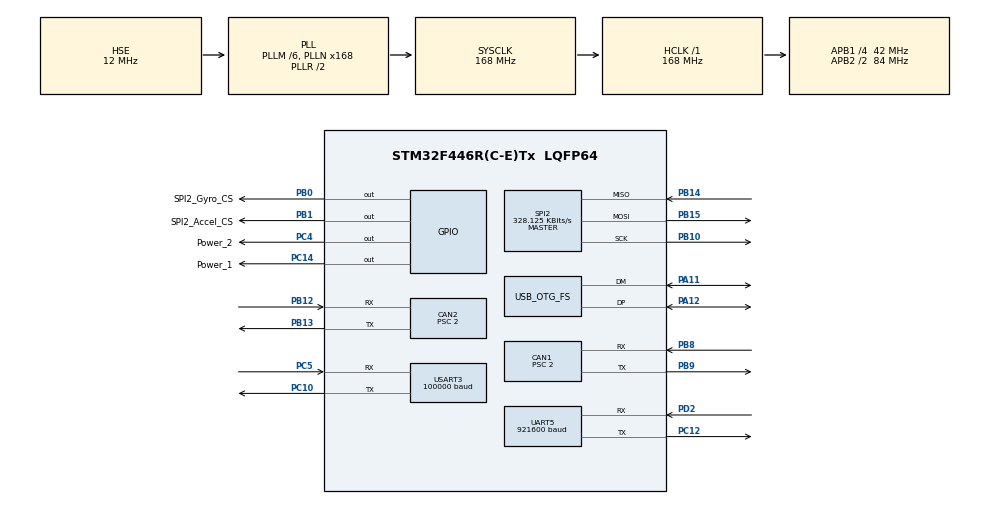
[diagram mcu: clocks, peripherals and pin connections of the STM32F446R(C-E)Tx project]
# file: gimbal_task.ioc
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CAN1.BS1=CAN_BS1_15TQ
CAN1.BS2=CAN_BS2_5TQ
CAN1.CalculateBaudRate=1000000
CAN1.CalculateTimeBit=1000
CAN1.CalculateTimeQuantum=47.61904761904762
CAN1.Prescaler=2
CAN2.BS1=CAN_BS1_15TQ
CAN2.BS2=CAN_BS2_5TQ
CAN2.CalculateBaudRate=1000000
CAN2.CalculateTimeBit=1000
CAN2.CalculateTimeQuantum=47.61904761904762
CAN2.Prescaler=2
Dma.Request0=SPI2_RX
Dma.Request1=SPI2_TX
Dma.Request2=USART3_RX
Dma.Request3=UART5_RX
Dma.SPI2_RX.0.Direction=DMA_PERIPH_TO_MEMORY
Dma.SPI2_RX.0.FIFOMode=DMA_FIFOMODE_DISABLE
Dma.SPI2_RX.0.Instance=DMA1_Stream3
Dma.SPI2_RX.0.MemDataAlignment=DMA_MDATAALIGN_BYTE
Dma.SPI2_RX.0.MemInc=DMA_MINC_ENABLE
Dma.SPI2_RX.0.Mode=DMA_NORMAL
Dma.SPI2_RX.0.PeriphDataAlignment=DMA_PDATAALIGN_BYTE
Dma.SPI2_RX.0.PeriphInc=DMA_PINC_DISABLE
Dma.SPI2_RX.0.Priority=DMA_PRIORITY_HIGH
Dma.SPI2_TX.1.Direction=DMA_MEMORY_TO_PERIPH
Dma.SPI2_TX.1.FIFOMode=DMA_FIFOMODE_DISABLE
Dma.SPI2_TX.1.Instance=DMA1_Stream4
Dma.SPI2_TX.1.MemDataAlignment=DMA_MDATAALIGN_BYTE
Dma.SPI2_TX.1.MemInc=DMA_MINC_ENABLE
Dma.SPI2_TX.1.Mode=DMA_NORMAL
Dma.SPI2_TX.1.PeriphDataAlignment=DMA_PDATAALIGN_BYTE
Dma.SPI2_TX.1.PeriphInc=DMA_PINC_DISABLE
Dma.SPI2_TX.1.Priority=DMA_PRIORITY_VERY_HIGH
Dma.UART5_RX.3.Direction=DMA_PERIPH_TO_MEMORY
Dma.UART5_RX.3.FIFOMode=DMA_FIFOMODE_DISABLE
Dma.UART5_RX.3.Instance=DMA1_Stream0
Dma.UART5_RX.3.MemDataAlignment=DMA_MDATAALIGN_BYTE
Dma.UART5_RX.3.MemInc=DMA_MINC_ENABLE
Dma.UART5_RX.3.Mode=DMA_NORMAL
Dma.UART5_RX.3.PeriphDataAlignment=DMA_PDATAALIGN_BYTE
Dma.UART5_RX.3.PeriphInc=DMA_PINC_DISABLE
Dma.UART5_RX.3.Priority=DMA_PRIORITY_LOW
Dma.USART3_RX.2.Direction=DMA_PERIPH_TO_MEMORY
Dma.USART3_RX.2.FIFOMode=DMA_FIFOMODE_DISABLE
Dma.USART3_RX.2.Instance=DMA1_Stream1
Dma.USART3_RX.2.MemDataAlignment=DMA_MDATAALIGN_BYTE
Dma.USART3_RX.2.MemInc=DMA_MINC_ENABLE
Dma.USART3_RX.2.Mode=DMA_NORMAL
Dma.USART3_RX.2.PeriphDataAlignment=DMA_PDATAALIGN_BYTE
Dma.USART3_RX.2.PeriphInc=DMA_PINC_DISABLE
Dma.USART3_RX.2.Priority=DMA_PRIORITY_LOW
FREERTOS.Tasks01=defaultTask,0,128,StartDefaultTask,Default,NULL,Dynamic,NULL,NULL;GIMABL,0,128,gimbal_task,As weak,NULL,Dynamic,NULL,NULL;INS,0,128,ins_task,As weak,NULL,Dynamic,NULL,NULL;SHOOT,0,128,shoot_task,As weak,NULL,Dynamic,NULL,NULL;STATE,0,128,state_task,As weak,NULL,Dynamic,NULL,NULL;VISION,0,128,vision_task,As weak,NULL,Dynamic,NULL,NULL
Mcu.Family=STM32F4
Mcu.Name=STM32F446R(C-E)Tx
Mcu.Package=LQFP64
NVIC.CAN1_RX0_IRQn=true\:5\:0\:false\:false\:true\:true\:true\:true\:true
NVIC.CAN2_RX0_IRQn=true\:5\:0\:false\:false\:true\:true\:true\:true\:true
NVIC.DMA1_Stream0_IRQn=true\:5\:0\:false\:false\:true\:true\:false\:true\:true
NVIC.DMA1_Stream1_IRQn=true\:5\:0\:false\:false\:true\:true\:false\:true\:true
NVIC.DMA1_Stream3_IRQn=true\:5\:0\:false\:false\:true\:true\:false\:true\:true
NVIC.DMA1_Stream4_IRQn=true\:5\:0\:false\:false\:true\:true\:false\:true\:true
NVIC.OTG_FS_IRQn=true\:5\:0\:false\:false\:true\:true\:false\:true\:true
NVIC.PriorityGroup=NVIC_PRIORITYGROUP_4
NVIC.UART5_IRQn=true\:5\:0\:false\:false\:true\:true\:true\:true\:true
NVIC.USART3_IRQn=true\:5\:0\:false\:false\:true\:true\:true\:true\:true
PA11.Mode=Device_Only
PA11.Signal=USB_OTG_FS_DM
PA12.Mode=Device_Only
PA12.Signal=USB_OTG_FS_DP
PA13.Mode=Serial_Wire
PA13.Signal=SYS_JTMS-SWDIO
PA14.Mode=Serial_Wire
PA14.Signal=SYS_JTCK-SWCLK
PB0.GPIO_Label=SPI2_Gyro_CS
PB0.Signal=GPIO_Output
PB1.GPIO_Label=SPI2_Accel_CS
PB1.Signal=GPIO_Output
PB10.Mode=Full_Duplex_Master
PB10.Signal=SPI2_SCK
PB12.Mode=CAN_Activate
PB12.Signal=CAN2_RX
PB13.Mode=CAN_Activate
PB13.Signal=CAN2_TX
PB14.Mode=Full_Duplex_Master
PB14.Signal=SPI2_MISO
PB15.Mode=Full_Duplex_Master
PB15.Signal=SPI2_MOSI
PB8.Mode=CAN_Activate
PB8.Signal=CAN1_RX
PB9.Mode=CAN_Activate
PB9.Signal=CAN1_TX
PC10.Mode=Asynchronous
PC10.Signal=USART3_TX
PC12.Mode=Asynchronous
PC12.Signal=UART5_TX
PC14-OSC32_IN.GPIO_Label=Power_1
PC14-OSC32_IN.Signal=GPIO_Output
PC4.GPIO_Label=Power_2
PC4.Signal=GPIO_Output
PC5.Mode=Asynchronous
PC5.Signal=USART3_RX
PD2.Mode=Asynchronous
PD2.Signal=UART5_RX
PH0-OSC_IN.Mode=HSE-External-Oscillator
PH0-OSC_IN.Signal=RCC_OSC_IN
PH1-OSC_OUT.Mode=HSE-External-Oscillator
PH1-OSC_OUT.Signal=RCC_OSC_OUT
ProjectManager.HeapSize=0x200
ProjectManager.StackSize=0x400
ProjectManager.TargetToolchain=MDK-ARM V5.32
RCC.AHBFreq_Value=168000000
RCC.APB1CLKDivider=RCC_HCLK_DIV4
RCC.APB1Freq_Value=42000000
RCC.APB1TimFreq_Value=84000000
RCC.APB2CLKDivider=RCC_HCLK_DIV2
RCC.APB2Freq_Value=84000000
RCC.APB2TimFreq_Value=168000000
RCC.CortexFreq_Value=168000000
RCC.HCLKFreq_Value=168000000
RCC.HSE_VALUE=12000000
RCC.PLLM=6
RCC.PLLN=168
RCC.PLLQ=7
RCC.PLLSourceVirtual=RCC_PLLSOURCE_HSE
RCC.SYSCLKFreq_VALUE=168000000
RCC.SYSCLKSource=RCC_SYSCLKSOURCE_PLLRCLK
RCC.USBFreq_Value=48000000
RCC.VCOOutputFreq_Value=336000000
SPI2.BaudRatePrescaler=SPI_BAUDRATEPRESCALER_128
SPI2.CLKPhase=SPI_PHASE_2EDGE
SPI2.CLKPolarity=SPI_POLARITY_HIGH
SPI2.CalculateBaudRate=328.125 KBits/s
SPI2.Direction=SPI_DIRECTION_2LINES
SPI2.Mode=SPI_MODE_MASTER
SPI2.VirtualType=VM_MASTER
UART5.BaudRate=921600
UART5.VirtualMode=Asynchronous
USART3.BaudRate=100000
USART3.VirtualMode=VM_ASYNC
USB_DEVICE.CLASS_NAME_FS=CDC
USB_DEVICE.VirtualMode-CDC_FS=Cdc
USB_DEVICE.VirtualModeFS=Cdc_FS
USB_OTG_FS.VirtualMode=Device_Only
VP_FREERTOS_VS_CMSIS_V1.Mode=CMSIS_V1
VP_USB_DEVICE_VS_USB_DEVICE_CDC_FS.Mode=CDC_FS
board=custom

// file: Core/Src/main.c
/* USER CODE BEGIN Header */
/**
  ******************************************************************************
  * @file           : main.c
  * @brief          : Main program body
  ******************************************************************************
  * @attention
  *
  * Copyright (c) 2025 STMicroelectronics.
  * All rights reserved.
  *
  * This software is licensed under terms that can be found in the LICENSE file
  * in the root directory of this software component.
  * If no LICENSE file comes with this software, it is provided AS-IS.
  *
  ******************************************************************************
  */
/* USER CODE END Header */
#include "main.h"
#include "cmsis_os.h"
#include "can.h"
#include "dma.h"
#include "spi.h"
#include "usart.h"
#include "usb_device.h"
#include "gpio.h"
#include "imu_task.h"
/* USER CODE BEGIN Includes */
#include "bsp_can.h"
#include "remote_control.h"
#include "tele_link.h"
/* USER CODE END Includes */

void SystemClock_Config(void);
void MX_FREERTOS_Init(void);

int main(void)
{

  /* MCU Configuration--------------------------------------------------------*/

  /* Reset of all peripherals, Initializes the Flash interface and the Systick. */
  HAL_Init();

  /* USER CODE BEGIN Init */
	int16_t BMI_INIT=0;
  /* USER CODE END Init */

  /* Configure the system clock */
  SystemClock_Config();

  /* Initialize all configured peripherals */
  MX_GPIO_Init();
  MX_DMA_Init();
  MX_CAN1_Init();
  MX_CAN2_Init();
  MX_SPI2_Init();
  MX_USART3_UART_Init();
  //MX_UART5_Init();
	//uart5_init_task();
  /* USER CODE BEGIN 2 */
	remote_control_init();
	//uart5_init_task();
	can_filter_init();
	while(BMI088_init()){;}
	DWT_Init(168);
	MX_UART5_Init();
	tele_link_init();
	//uart5_init_task();
  /* USER CODE END 2 */
  /* Call init function for freertos objects (in cmsis_os2.c) */
  MX_FREERTOS_Init();

  /* Start scheduler */
  osKernelStart();

  /* We should never get here as control is now taken by the scheduler */

  /* Infinite loop */
  while (1)
  {

  }
}

void SystemClock_Config(void)
{
  RCC_OscInitTypeDef RCC_OscInitStruct = {0};
  RCC_ClkInitTypeDef RCC_ClkInitStruct = {0};

  /** Configure the main internal regulator output voltage
  */
  __HAL_RCC_PWR_CLK_ENABLE();
  __HAL_PWR_VOLTAGESCALING_CONFIG(PWR_REGULATOR_VOLTAGE_SCALE1);

  /** Initializes the RCC Oscillators according to the specified parameters
  * in the RCC_OscInitTypeDef structure.
  */
  RCC_OscInitStruct.OscillatorType = RCC_OSCILLATORTYPE_HSE;
  RCC_OscInitStruct.HSEState = RCC_HSE_ON;
  RCC_OscInitStruct.PLL.PLLState = RCC_PLL_ON;
  RCC_OscInitStruct.PLL.PLLSource = RCC_PLLSOURCE_HSE;
  RCC_OscInitStruct.PLL.PLLM = 6;
  RCC_OscInitStruct.PLL.PLLN = 168;
  RCC_OscInitStruct.PLL.PLLP = RCC_PLLP_DIV2;
  RCC_OscInitStruct.PLL.PLLQ = 7;
  RCC_OscInitStruct.PLL.PLLR = 2;
  if (HAL_RCC_OscConfig(&RCC_OscInitStruct) != HAL_OK)
  {
    Error_Handler();
  }

  /** Initializes the CPU, AHB and APB buses clocks
  */
  RCC_ClkInitStruct.ClockType = RCC_CLOCKTYPE_HCLK|RCC_CLOCKTYPE_SYSCLK
                              |RCC_CLOCKTYPE_PCLK1|RCC_CLOCKTYPE_PCLK2;
  RCC_ClkInitStruct.SYSCLKSource = RCC_SYSCLKSOURCE_PLLRCLK;
  RCC_ClkInitStruct.AHBCLKDivider = RCC_SYSCLK_DIV1;
  RCC_ClkInitStruct.APB1CLKDivider = RCC_HCLK_DIV4;
  RCC_ClkInitStruct.APB2CLKDivider = RCC_HCLK_DIV2;

  if (HAL_RCC_ClockConfig(&RCC_ClkInitStruct, FLASH_LATENCY_5) != HAL_OK)
  {
    Error_Handler();
  }
}

void Error_Handler(void)
{
  __disable_irq();
  while (1)
  {
  }
}

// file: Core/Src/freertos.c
/* USER CODE BEGIN Header */
/**
  ******************************************************************************
  * File Name          : freertos.c
  * Description        : Code for freertos applications
  ******************************************************************************
  * @attention
  *
  * Copyright (c) 2025 STMicroelectronics.
  * All rights reserved.
  *
  * This software is licensed under terms that can be found in the LICENSE file
  * in the root directory of this software component.
  * If no LICENSE file comes with this software, it is provided AS-IS.
  *
  ******************************************************************************
  */
/* USER CODE END Header */

#include "FreeRTOS.h"
#include "task.h"
#include "main.h"
#include "cmsis_os.h"

osThreadId defaultTaskHandle;
osThreadId GIMABLHandle;
osThreadId INSHandle;
osThreadId SHOOTHandle;
osThreadId STATEHandle;
osThreadId VISIONHandle;

void StartDefaultTask(void const * argument);
void gimbal_task(void const * argument);
void ins_task(void const * argument);
void shoot_task(void const * argument);
void state_task(void const * argument);
void vision_task(void const * argument);

extern void MX_USB_DEVICE_Init(void);
void MX_FREERTOS_Init(void); /* (MISRA C 2004 rule 8.1) */

/* GetIdleTaskMemory prototype (linked to static allocation support) */
void vApplicationGetIdleTaskMemory( StaticTask_t **ppxIdleTaskTCBBuffer, StackType_t **ppxIdleTaskStackBuffer, uint32_t *pulIdleTaskStackSize );

/* USER CODE BEGIN GET_IDLE_TASK_MEMORY */
static StaticTask_t xIdleTaskTCBBuffer;
static StackType_t xIdleStack[configMINIMAL_STACK_SIZE];

void vApplicationGetIdleTaskMemory( StaticTask_t **ppxIdleTaskTCBBuffer, StackType_t **ppxIdleTaskStackBuffer, uint32_t *pulIdleTaskStackSize )
{
  *ppxIdleTaskTCBBuffer = &xIdleTaskTCBBuffer;
  *ppxIdleTaskStackBuffer = &xIdleStack[0];
  *pulIdleTaskStackSize = configMINIMAL_STACK_SIZE;
  /* place for user code */
}
/* USER CODE END GET_IDLE_TASK_MEMORY */

void MX_FREERTOS_Init(void) {

  /* Create the thread(s) */
  /* definition and creation of defaultTask */
  osThreadDef(defaultTask, StartDefaultTask, osPriorityNormal, 0, 256);
  defaultTaskHandle = osThreadCreate(osThread(defaultTask), NULL);

  /* definition and creation of GIMABL */
  osThreadDef(GIMABL, gimbal_task, osPriorityNormal, 0, 256);
  GIMABLHandle = osThreadCreate(osThread(GIMABL), NULL);

  /* definition and creation of INS */
  osThreadDef(INS, ins_task, osPriorityNormal, 0, 512);
  INSHandle = osThreadCreate(osThread(INS), NULL);

  /* definition and creation of SHOOT */
  osThreadDef(SHOOT, shoot_task, osPriorityNormal, 0, 512);
  SHOOTHandle = osThreadCreate(osThread(SHOOT), NULL);

  /* definition and creation of STATE */
  osThreadDef(STATE, state_task, osPriorityNormal, 0, 256);
  STATEHandle = osThreadCreate(osThread(STATE), NULL);

  /* definition and creation of VISION */
  osThreadDef(VISION, vision_task, osPriorityNormal, 0, 128);
  VISIONHandle = osThreadCreate(osThread(VISION), NULL);

}

void StartDefaultTask(void const * argument)
{
  /* init code for USB_DEVICE */
  MX_USB_DEVICE_Init();
  for(;;)
  {
    osDelay(1);
  }
}

__weak void gimbal_task(void const * argument)
{
  for(;;)
  {
    osDelay(1);
  }
}

__weak void ins_task(void const * argument)
{
  for(;;)
  {
    osDelay(1);
  }
}

__weak void shoot_task(void const * argument)
{
  for(;;)
  {
    osDelay(1);
  }
}

__weak void state_task(void const * argument)
{
  for(;;)
  {
    osDelay(1);
  }
}

__weak void vision_task(void const * argument)
{
  for(;;)
  {
    osDelay(1);
  }
}
